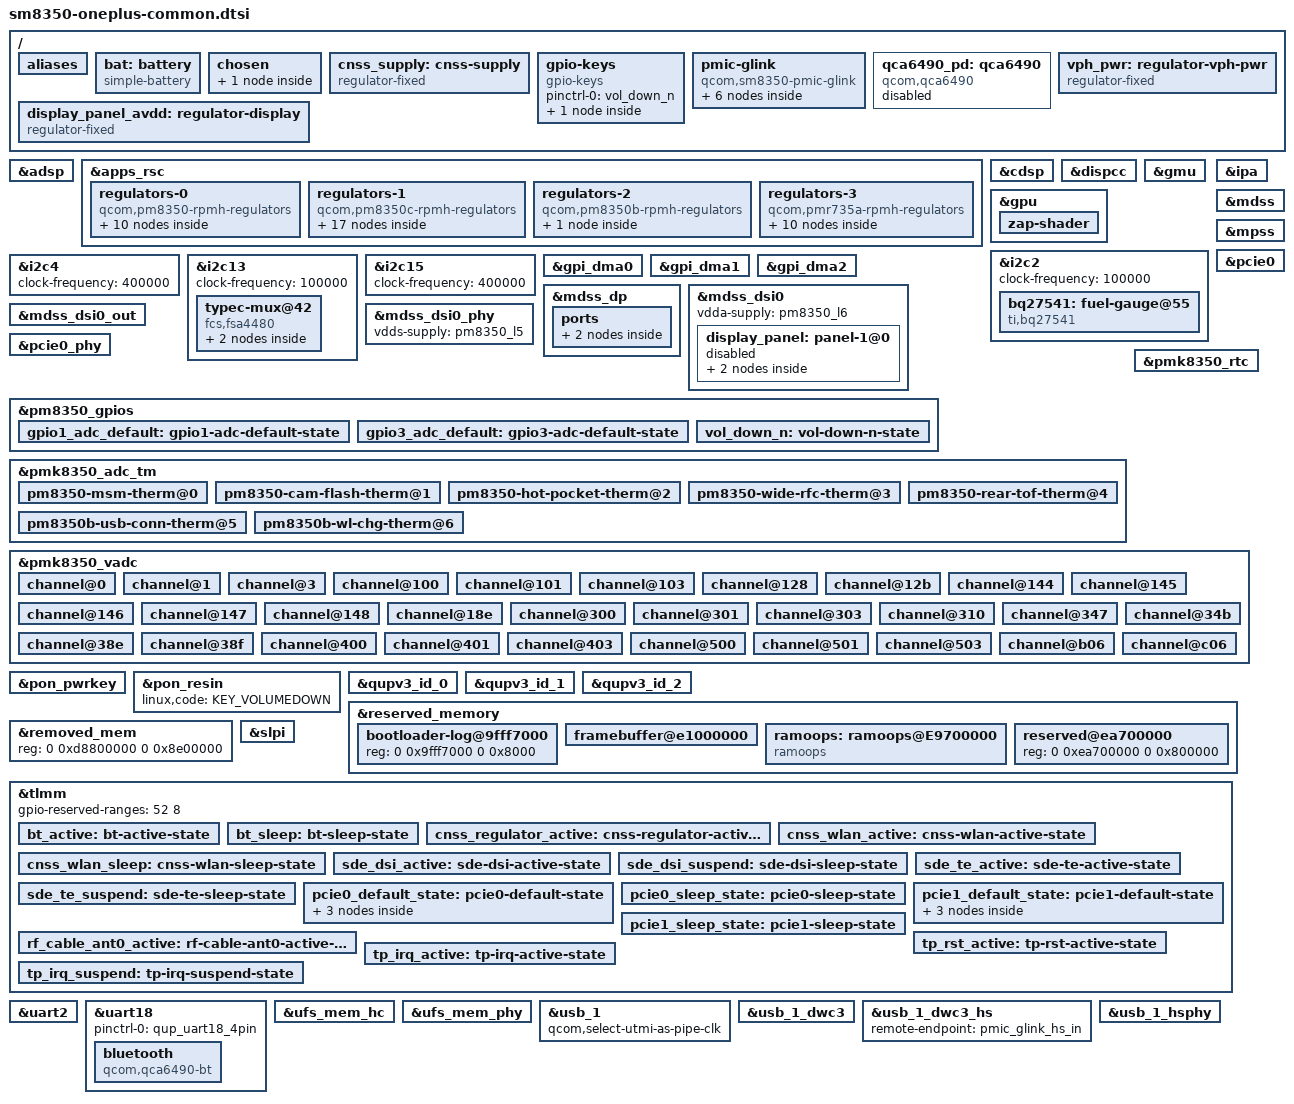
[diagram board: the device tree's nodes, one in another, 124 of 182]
// SPDX-License-Identifier: BSD-3-Clause
/*
 * Copyright (c) 2023 Igalia S.L.
 * Authors:
 *	Nia Espera <nespera@igalia.com>
 */

#include <dt-bindings/iio/qcom,spmi-adc7-pm8350.h>
#include <dt-bindings/iio/qcom,spmi-adc7-pm8350b.h>
#define SMB139x_1_SID 0x0b
#define SMB139x_2_SID 0x0c
#include <dt-bindings/iio/qcom,spmi-adc7-smb139x.h>
#include <dt-bindings/pinctrl/qcom,pmic-gpio.h>
#include <dt-bindings/regulator/qcom,rpmh-regulator.h>
#include "sm8350.dtsi"
#include "pm8350.dtsi"
#include "pm8350b.dtsi"
#include "pm8350c.dtsi"
#include "pmk8350.dtsi"
#include "pmr735a.dtsi"
#include "pmr735b.dtsi"

/ {
	chassis-type = "handset";
	interrupt-parent = <&intc>;

	aliases {
		bluetooth = &bluetooth;
		serial0 = &uart2;
		serial1 = &uart18;
	};

	bat: battery {
		compatible = "simple-battery";
		device-chemistry = "lithium-ion";
		voltage-min-design-microvolt = <3200000>;
		energy-full-design-microwatt-hours = <15840000>;
		charge-full-design-microamp-hours = <2225000>;
	};

	chosen {
		#address-cells = <2>;
		#size-cells = <2>;
		ranges;

		framebuffer: framebuffer@e4d00000 {
			compatible = "simple-framebuffer";
			reg = <0 0xe4d00000 0 0x2400000>;
			width = <1080>;
			height = <2412>;
			stride = <(1080 * 4)>;
			format = "a8r8g8b8";
			/*
			 * That's (going to be) a lot of clocks, but it's
			 * necessary due to unused clk cleanup & no panel
			 * driver yet.
			 */
			clocks = <&gcc GCC_DISP_HF_AXI_CLK>,
				 <&gcc GCC_DISP_SF_AXI_CLK>;
		};
	};

	cnss_supply: cnss-supply {
		compatible = "regulator-fixed";
		regulator-name = "wcnss_regulator";
		regulator-min-microvolt = <1900000>;
		regulator-max-microvolt = <1900000>;

		enable-active-high;

		pinctrl-0 = <&cnss_regulator_active>;
		pinctrl-names = "default";

		gpio = <&tlmm 201 GPIO_ACTIVE_HIGH>;
	};

	/*
	gpio_i2c4: gpio-i2c {
		compatible = "i2c-gpio";
		sda-gpios = <&tlmm 20 (GPIO_ACTIVE_HIGH|GPIO_OPEN_DRAIN)>;
		scl-gpios = <&tlmm 21 (GPIO_ACTIVE_HIGH|GPIO_OPEN_DRAIN)>;
		//#address-cells = <1>;
		//#size-cells = <0>;

		pinctrl-names = "default";
		pinctrl-0 = <&qup_i2c4_default>, <&tp_enable_2v8>;
	};
	*/

	gpio-keys {
		compatible = "gpio-keys";

		pinctrl-0 = <&vol_down_n>;
		pinctrl-names = "default";

		key-vol-down {
			label = "Volume Down";
			linux,code = <KEY_VOLUMEDOWN>;
			gpios = <&pm8350_gpios 6 GPIO_ACTIVE_LOW>;
			debounce-interval = <15>;
			linux,can-disable;
			wakeup-source;
		};
	};

	pmic-glink {
		compatible = "qcom,sm8350-pmic-glink", "qcom,pmic-glink";
		#address-cells = <1>;
		#size-cells = <0>;

		connector@0 {
			compatible = "usb-c-connector";
			reg = <0>;
			power-role = "dual";
			data-role = "dual";

			ports {
				#address-cells = <1>;
				#size-cells = <0>;

				port@0 {
					reg = <0>;

					pmic_glink_hs_in: endpoint {
						remote-endpoint = <&usb_1_dwc3_hs>;
					};
				};

				/* USB3 not working, so no port@1 */

				port@2 {
					reg = <2>;

					pmic_glink_sbu: endpoint {
						remote-endpoint = <&fsa4480_sbu_mux>;
					};
				};
			};
		};
	};

	qca6490_pd: qca6490 {
		compatible = "qcom,qca6490";
		#power-domain-cells = <0>;

		vddaonbt-supply = <&pm8350_s11>;
		vddaonwl-supply = <&pmr735a_s2>;
		vddasd-supply = <&pmr735a_l7>;
		vddrfa1-supply = <&pm8350c_s1>;
		vddrfa2-supply = <&pm8350_s12>;
		vddrfa3-supply = <&pm8350c_s1>;
		vddpcie1-supply = <&cnss_supply>;
		vddpcie2-supply = <&pm8350c_s1>;
		vddio-supply = <&pm8350_s10>;

		pinctrl-0 = <&cnss_wlan_sleep>;
		pinctrl-1 = <&cnss_wlan_active>;
		pinctrl-names = "default", "active";

		status = "disabled";
	};

	display_panel_avdd: regulator-display {
		compatible = "regulator-fixed";
		regulator-name = "display_panel_avdd";
		regulator-min-microvolt = <5500000>;
		regulator-max-microvolt = <5500000>;
		regulator-enable-ramp-delay = <233>;

		enable-active-high;
		regulator-boot-on;
	};

	vph_pwr: regulator-vph-pwr {
		compatible = "regulator-fixed";
		regulator-name = "vph_pwr";
		regulator-min-microvolt = <3700000>;
		regulator-max-microvolt = <3700000>;

		regulator-always-on;
		regulator-boot-on;
	};
};

&adsp {
	firmware-name = "qcom/sm8350/OnePlus/lemonade/adsp.mbn";
	status = "okay";
};

&apps_rsc {
	regulators-0 {
		compatible = "qcom,pm8350-rpmh-regulators";
		qcom,pmic-id = "b";

		vdd-s1-supply = <&vph_pwr>;
		vdd-s2-supply = <&vph_pwr>;
		vdd-s3-supply = <&vph_pwr>;
		vdd-s4-supply = <&vph_pwr>;
		vdd-s5-supply = <&vph_pwr>;
		vdd-s6-supply = <&vph_pwr>;
		vdd-s7-supply = <&vph_pwr>;
		vdd-s8-supply = <&vph_pwr>;
		vdd-s9-supply = <&vph_pwr>;
		vdd-s10-supply = <&vph_pwr>;
		vdd-s11-supply = <&vph_pwr>;
		vdd-s12-supply = <&vph_pwr>;

		vdd-l1-l4-supply = <&pm8350_s11>;
		vdd-l2-l7-supply = <&vreg_bob>;
		vdd-l3-l5-supply = <&vreg_bob>;
		vdd-l6-l9-l10-supply = <&pm8350_s11>;
		vdd-l8-supply = <&pmr735a_s2>;

		/*
		 * ARC regulators:
		 * S5 - mx.lvl
		 * S6 - gfx.lvl
		 * S9 - mxc.lvl
		 */

		pm8350_s10: smps10 {
			regulator-name = "pm8350_s10";
			regulator-min-microvolt = <1800000>;
			regulator-max-microvolt = <1800000>;
			regulator-initial-mode = <RPMH_REGULATOR_MODE_HPM>;
		};

		pm8350_s11: smps11 {
			regulator-name = "pm8350_s11";
			regulator-min-microvolt = <752000>;
			regulator-max-microvolt = <1012000>;
			regulator-initial-mode = <RPMH_REGULATOR_MODE_HPM>;
		};

		pm8350_s12: smps12 {
			regulator-name = "pm8350_s12";
			regulator-min-microvolt = <1224000>;
			regulator-max-microvolt = <1360000>;
			regulator-initial-mode = <RPMH_REGULATOR_MODE_HPM>;
		};

		pm8350_l1: ldo1 {
			regulator-name = "pm8350_l1";
			regulator-min-microvolt = <912000>;
			regulator-max-microvolt = <920000>;
			regulator-initial-mode = <RPMH_REGULATOR_MODE_HPM>;
		};

		pm8350_l2: ldo2 {
			regulator-name = "pm8350_l2";
			regulator-min-microvolt = <3072000>;
			regulator-max-microvolt = <3072000>;
			regulator-initial-mode = <RPMH_REGULATOR_MODE_HPM>;
		};

		pm8350_l3: ldo3 {
			regulator-name = "pm8350_l3";
			regulator-min-microvolt = <904000>;
			regulator-max-microvolt = <904000>;
			regulator-initial-mode = <RPMH_REGULATOR_MODE_HPM>;
		};

		/* L4 - lmx.lvl (ARC) */

		pm8350_l5: ldo5 {
			regulator-name = "pm8350_l5";
			regulator-min-microvolt = <880000>;
			regulator-max-microvolt = <888000>;
			regulator-initial-mode = <RPMH_REGULATOR_MODE_HPM>;
			regulator-allow-set-load;
			regulator-allowed-modes = <RPMH_REGULATOR_MODE_LPM
						   RPMH_REGULATOR_MODE_HPM>;
		};

		pm8350_l6: ldo6 {
			regulator-name = "pm8350_l6";
			regulator-min-microvolt = <1200000>;
			regulator-max-microvolt = <1208000>;
			regulator-initial-mode = <RPMH_REGULATOR_MODE_HPM>;
			regulator-allow-set-load;
			regulator-allowed-modes = <RPMH_REGULATOR_MODE_LPM
						   RPMH_REGULATOR_MODE_HPM>;
		};

		pm8350_l7: ldo7 {
			regulator-name = "pm8350_l7";
			regulator-min-microvolt = <2400000>;
			regulator-max-microvolt = <3008000>;
			regulator-initial-mode = <RPMH_REGULATOR_MODE_HPM>;
			regulator-allow-set-load;
			regulator-allowed-modes = <RPMH_REGULATOR_MODE_LPM
						   RPMH_REGULATOR_MODE_HPM>;
		};

		/* L8 - lcx.lvl (ARC) */

		pm8350_l9: ldo9 {
			regulator-name = "pm8350_l9";
			regulator-min-microvolt = <1200000>;
			regulator-max-microvolt = <1200000>;
			regulator-initial-mode = <RPMH_REGULATOR_MODE_HPM>;
			regulator-allow-set-load;
			regulator-allowed-modes = <RPMH_REGULATOR_MODE_LPM
						   RPMH_REGULATOR_MODE_HPM>;
		};
	};

	regulators-1 {
		compatible = "qcom,pm8350c-rpmh-regulators";
		qcom,pmic-id = "c";

		vdd-s1-supply = <&vph_pwr>;
		vdd-s2-supply = <&vph_pwr>;
		vdd-s3-supply = <&vph_pwr>;
		vdd-s4-supply = <&vph_pwr>;
		vdd-s5-supply = <&vph_pwr>;
		vdd-s6-supply = <&vph_pwr>;
		vdd-s7-supply = <&vph_pwr>;
		vdd-s8-supply = <&vph_pwr>;
		vdd-s9-supply = <&vph_pwr>;
		vdd-s10-supply = <&vph_pwr>;

		vdd-l1-l12-supply = <&pm8350c_s1>;
		vdd-l2-l8-supply = <&pm8350c_s1>;
		vdd-l3-l4-l5-l7-l13-supply = <&vreg_bob>;
		vdd-l6-l9-l11-supply = <&vreg_bob>;
		vdd-l10-supply = <&pm8350_s12>;

		vdd-bob-supply = <&vph_pwr>;

		pm8350c_s1: smps1 {
			regulator-name = "pm8350c_s1";
			regulator-min-microvolt = <1800000>;
			regulator-max-microvolt = <1952000>;
			regulator-initial-mode = <RPMH_REGULATOR_MODE_HPM>;
		};

		/* S2 - ebi.lvl (ARC) */

		pm8350c_s3: smps3 {
			regulator-name = "pm8350c_s3";
			regulator-min-microvolt = <300000>;
			regulator-max-microvolt = <704000>;
			regulator-initial-mode = <RPMH_REGULATOR_MODE_HPM>;
		};

		/*
		 * ARC regulators:
		 * S4 - mss.lvl
		 * S6 - cx.lvl
		 * S8 - mmcx.lvl
		 */

		pm8350c_s10: smps10 {
			regulator-name = "pm8350c_s10";
			regulator-min-microvolt = <1048000>;
			regulator-max-microvolt = <1128000>;
			regulator-initial-mode = <RPMH_REGULATOR_MODE_HPM>;
		};

		pm8350c_l1: ldo1 {
			regulator-name = "pm8350c_l1";
			regulator-min-microvolt = <1800000>;
			regulator-max-microvolt = <1800000>;
			regulator-initial-mode = <RPMH_REGULATOR_MODE_HPM>;
		};

		pm8350c_l2: ldo2 {
			regulator-name = "pm8350c_l2";
			regulator-min-microvolt = <1800000>;
			regulator-max-microvolt = <1800000>;
			regulator-initial-mode = <RPMH_REGULATOR_MODE_HPM>;
		};

		pm8350c_l3: ldo3 {
			regulator-name = "pm8350c_l3";
			regulator-min-microvolt = <3000000>;
			regulator-max-microvolt = <3300000>;
			regulator-initial-mode = <RPMH_REGULATOR_MODE_HPM>;
		};

		pm8350c_l4: ldo4 {
			regulator-name = "pm8350c_l4";
			regulator-min-microvolt = <1704000>;
			regulator-max-microvolt = <3000000>;
			regulator-initial-mode = <RPMH_REGULATOR_MODE_HPM>;
		};

		pm8350c_l5: ldo5 {
			regulator-name = "pm8350c_l5";
			regulator-min-microvolt = <1704000>;
			regulator-max-microvolt = <3000000>;
			regulator-initial-mode = <RPMH_REGULATOR_MODE_HPM>;
		};

		pm8350c_l6: ldo6 {
			regulator-name = "pm8350c_l6";
			regulator-min-microvolt = <1800000>;
			regulator-max-microvolt = <2960000>;
			regulator-initial-mode = <RPMH_REGULATOR_MODE_HPM>;
		};

		pm8350c_l7: ldo7 {
			regulator-name = "pm8350c_l7";
			regulator-min-microvolt = <3008000>;
			regulator-max-microvolt = <3008000>;
			regulator-initial-mode = <RPMH_REGULATOR_MODE_HPM>;
		};

		pm8350c_l8: ldo8 {
			regulator-name = "pm8350c_l8";
			regulator-min-microvolt = <1800000>;
			regulator-max-microvolt = <1800000>;
			regulator-initial-mode = <RPMH_REGULATOR_MODE_HPM>;
		};

		pm8350c_l9: ldo9 {
			regulator-name = "pm8350c_l9";
			regulator-min-microvolt = <2800000>;
			regulator-max-microvolt = <3008000>;
			regulator-initial-mode = <RPMH_REGULATOR_MODE_HPM>;
		};

		pm8350c_l10: ldo10 {
			regulator-name = "pm8350c_l10";
			regulator-min-microvolt = <1200000>;
			regulator-max-microvolt = <1200000>;
			regulator-initial-mode = <RPMH_REGULATOR_MODE_HPM>;
		};

		pm8350c_l11: ldo11 {
			regulator-name = "pm8350c_l11";
			regulator-min-microvolt = <2400000>;
			regulator-max-microvolt = <3008000>;
			regulator-initial-mode = <RPMH_REGULATOR_MODE_HPM>;
		};

		pm8350c_l12: ldo12 {
			regulator-name = "pm8350c_l12";
			regulator-min-microvolt = <1800000>;
			regulator-max-microvolt = <2000000>;
			regulator-initial-mode = <RPMH_REGULATOR_MODE_HPM>;
		};

		pm8350c_l13: ldo13 {
			regulator-name = "pm8350c_l13";
			regulator-min-microvolt = <3000000>;
			regulator-max-microvolt = <3200000>;
			regulator-initial-mode = <RPMH_REGULATOR_MODE_HPM>;
		};

		vreg_bob: bob {
			regulator-name = "vreg_bob";
			regulator-min-microvolt = <3400000>;
			regulator-max-microvolt = <3960000>;
			regulator-initial-mode = <RPMH_REGULATOR_MODE_AUTO>;
		};
	};

	regulators-2 {
		compatible = "qcom,pm8350b-rpmh-regulators";
		qcom,pmic-id = "d";

		vdd-l1-supply = <&pm8350_s12>;

		pm8350b_l1: ldo1 {
			regulator-name = "pm8350b_l1";
			regulator-min-microvolt = <1200000>;
			regulator-max-microvolt = <1200000>;
			regulator-initial-mode = <RPMH_REGULATOR_MODE_HPM>;
			regulator-allowed-modes = <RPMH_REGULATOR_MODE_LPM
						   RPMH_REGULATOR_MODE_HPM>;
		};
	};

	regulators-3 {
		compatible = "qcom,pmr735a-rpmh-regulators";
		qcom,pmic-id = "e";

		vdd-s1-supply = <&vph_pwr>;
		vdd-s2-supply = <&vph_pwr>;
		vdd-s3-supply = <&vph_pwr>;

		vdd-l1-l2-supply = <&pmr735a_s2>;
		vdd-l3-supply = <&pmr735a_s1>;
		vdd-l4-supply = <&pm8350c_s1>;
		vdd-l5-l6-supply = <&pm8350c_s1>;
		vdd-l7-bob-supply = <&vreg_bob>;

		pmr735a_s1: smps1 {
			regulator-name = "pmr735a_s1";
			regulator-min-microvolt = <1200000>;
			regulator-max-microvolt = <1280000>;
		};

		pmr735a_s2: smps2 {
			regulator-name = "pmr735a_s2";
			regulator-min-microvolt = <500000>;
			regulator-max-microvolt = <976000>;
		};

		pmr735a_s3: smps3 {
			regulator-name = "pmr735a_s3";
			regulator-min-microvolt = <2208000>;
			regulator-max-microvolt = <2352000>;
		};

		pmr735a_l1: ldo1 {
			regulator-name = "pmr735a_l1";
			regulator-min-microvolt = <912000>;
			regulator-max-microvolt = <912000>;
		};

		pmr735a_l2: ldo2 {
			regulator-name = "pmr735a_l2";
			regulator-min-microvolt = <1200000>;
			regulator-max-microvolt = <1200000>;
		};

		pmr735a_l3: ldo3 {
			regulator-name = "pmr735a_l3";
			regulator-min-microvolt = <1200000>;
			regulator-max-microvolt = <1200000>;
		};

		pmr735a_l4: ldo4 {
			regulator-name = "pmr735a_l4";
			regulator-min-microvolt = <1776000>;
			regulator-max-microvolt = <1872000>;
		};

		pmr735a_l5: ldo5 {
			regulator-name = "pmr735a_l5";
			regulator-min-microvolt = <800000>;
			regulator-max-microvolt = <800000>;
		};

		pmr735a_l6: ldo6 {
			regulator-name = "pmr735a_l6";
			regulator-min-microvolt = <480000>;
			regulator-max-microvolt = <904000>;
		};

		pmr735a_l7: ldo7 {
			regulator-name = "pmr735a_l7";
			regulator-min-microvolt = <2800000>;
			regulator-max-microvolt = <2800000>;
		};
	};
};

&cdsp {
	firmware-name = "qcom/sm8350/OnePlus/lemonade/cdsp.mbn";
	status = "okay";
};

&dispcc {
	//status = "okay";
};

&gmu {
	/* FIXME: check_dtbs complains */
	//firmware-name = "qcom/sm8350/lemonade/a660_gmu.bin";
};

&gpu {
	//status = "okay";

	zap-shader {
		memory-region = <&pil_gpu_mem>;
		firmware-name = "qcom/sm8350/lemonade/a660_zap.mbn";
	};
};

&i2c2 {
	clock-frequency = <100000>;
	status = "okay";

	bq27541: fuel-gauge@55 {
		compatible = "ti,bq27541";
		reg = <0x55>;
		monitored-battery = <&bat>;
	};
};


&i2c4 {
	clock-frequency = <400000>;
	status = "okay";

	/* Touchscreens: Syna TCM oncell or Samsung s6sy761 */
};

&i2c13 {
	clock-frequency = <100000>;
	status = "okay";

	typec-mux@42 {
		compatible = "fcs,fsa4480";
		reg = <0x42>;

		interrupts-extended = <&tlmm 2 IRQ_TYPE_LEVEL_LOW>;

		vcc-supply = <&vreg_bob>;
		mode-switch;
		orientation-switch;

		port {
			fsa4480_sbu_mux: endpoint {
				remote-endpoint = <&pmic_glink_sbu>;
			};
		};
	};

	/* Qualcomm PM8008i/PM8008j @ 8, 9, c, d */
};

&i2c15 {
	clock-frequency = <400000>;
	status = "okay";

	/* sn-nci NFC controller @ 28 */
};

&gpi_dma0 {
	status = "okay";
};

&gpi_dma1 {
	status = "okay";
};

&gpi_dma2 {
	status = "okay";
};

&ipa {
	qcom,gsi-loader = "self";
	memory-region = <&pil_ipa_fw_mem>;
	firmware-name = "qcom/sm8350/OnePlus/lemonade/ipa_fws.mbn";
	status = "okay";
};

&mdss {
	//status = "okay";
};

&mdss_dp {
	//status = "okay";

	ports {
		port@1 {
			reg = <1>;

			endpoint {
			};
		};
	};
};

&mdss_dsi0 {
	vdda-supply = <&pm8350_l6>;

	//status = "okay";

	/* Common properties for OnePlus 9 and 9 Pro */
	display_panel: panel-1@0 {
		reg = <0>;

		pinctrl-0 = <&sde_dsi_active &sde_te_active>;
		pinctrl-1 = <&sde_dsi_suspend &sde_te_suspend>;
		pinctrl-names = "default", "sleep";

		reset-gpios = <&tlmm 24 GPIO_ACTIVE_LOW>;

		vdd-supply = <&pm8350c_l13>;
		vddio-supply = <&pm8350c_l12>;
		avdd-supply = <&display_panel_avdd>;
		//clocks = <&rpmhcc RPMH_DIV_CLK1>;
		//clock-names = "div_clk";
		//clocks = <&mdss_dsi0_phy DISP_CC_MDSS_>

		status = "disabled";

		port {
			panel_in: endpoint {
				remote-endpoint = <&mdss_dsi0_out>;
			};
		};
	};
};

&mdss_dsi0_out {
	remote-endpoint = <&panel_in>;
	data-lanes = <0 1 2 3>;
};

&mdss_dsi0_phy {
	vdds-supply = <&pm8350_l5>;
	//status = "okay";
};

&mpss {
	firmware-name = "qcom/sm8350/OnePlus/lemonade/modem.mbn";
};

&pcie0 {
	pinctrl-0 = <&pcie0_default_state>;//, <&pcie0_sleep_state>;
	pinctrl-names = "default";//, "sleep";

	//power-domains = <&qca6490_pd>;

	perst-gpios = <&tlmm 94 GPIO_ACTIVE_HIGH>;
	wake-gpios = <&tlmm 96 GPIO_ACTIVE_HIGH>;

	status = "okay";
};

&pcie0_phy {
	vdda-phy-supply = <&pm8350_l5>;
	vdda-pll-supply = <&pm8350_l6>;

	power-domains = <&qca6490_pd>;

	status = "okay";
};

&pm8350_gpios {
	gpio1_adc_default: gpio1-adc-default-state {
		pins = "gpio1";
		function = "normal";
		bias-high-impedance;
		bias-disable;
	};

	gpio3_adc_default: gpio3-adc-default-state {
		pins = "gpio3";
		function = "normal";
		bias-high-impedance;
		bias-disable;
	};

	vol_down_n: vol-down-n-state {
		pins = "gpio6";
		function = "normal";
		power-source = <1>;
		bias-pull-up;
		input-enable;
	};
};

&pmk8350_adc_tm {
	status = "okay";

	pm8350-msm-therm@0 {
		reg = <0>;
		io-channels = <&pmk8350_vadc PM8350_ADC7_AMUX_THM1_100K_PU(1)>;
		qcom,ratiometric;
		qcom,hw-settle-time-us = <200>;
	};

	pm8350-cam-flash-therm@1 {
		reg = <1>;
		io-channels = <&pmk8350_vadc PM8350_ADC7_AMUX_THM2_100K_PU(1)>;
		qcom,ratiometric;
		qcom,hw-settle-time-us = <200>;
	};

	pm8350-hot-pocket-therm@2 {
		reg = <2>;
		io-channels = <&pmk8350_vadc PM8350_ADC7_AMUX_THM3_100K_PU(1)>;
		qcom,ratiometric;
		qcom,hw-settle-time-us = <200>;
	};

	pm8350-wide-rfc-therm@3 {
		reg = <3>;
		io-channels = <&pmk8350_vadc PM8350_ADC7_AMUX_THM4_100K_PU(1)>;
		qcom,ratiometric;
		qcom,hw-settle-time-us = <200>;
	};

	pm8350-rear-tof-therm@4 {
		reg = <4>;
		io-channels = <&pmk8350_vadc PM8350_ADC7_AMUX_THM5_100K_PU(1)>;
		qcom,ratiometric;
		qcom,hw-settle-time-us = <200>;
	};

	pm8350b-usb-conn-therm@5 {
		reg = <5>;
		io-channels = <&pmk8350_vadc PM8350B_ADC7_AMUX_THM4_100K_PU>;
		qcom,ratiometric;
		qcom,hw-settle-time-us = <200>;
	};

	pm8350b-wl-chg-therm@6 {
		reg = <6>;
		io-channels = <&pmk8350_vadc PM8350B_ADC7_GPIO2_100K_PU>;
		qcom,ratiometric;
		qcom,hw-settle-time-us = <200>;
	};
};

&pmk8350_rtc {
	status = "okay";
};

&pmk8350_vadc {
	pinctrl-0 = <&gpio1_adc_default>, <&gpio3_adc_default>;
	pinctrl-names = "default";

	channel@0 {
		reg = <0x00>;
		qcom,pre-scaling = <1 1>;
		label = "pmk8350_ref_gnd";
	};

	channel@1 {
		reg = <0x01>;
		qcom,pre-scaling = <1 1>;
		label = "pmk8350_vref_1p25";
	};

	channel@3 {
		reg = <0x03>;
		qcom,pre-scaling = <1 1>;
		label = "pmk8350_die_temp";
	};

	channel@100 {
		reg = <0x100>;
		qcom,pre-scaling = <1 1>;
		label = "pm8350_ref_gnd";
	};

	channel@101 {
		reg = <0x101>;
		qcom,pre-scaling = <1 1>;
		label = "pm8350_vref_1p25";
	};

	channel@103 {
		reg = <0x103>;
		qcom,pre-scaling = <1 1>;
		label = "pm8350_die_temp";
	};

	channel@128 {
		reg = <0x128>;
		qcom,ratiometric;
		qcom,hw-settle-time = <700>;
		qcom,pre-scaling = <1 1>;
		label = "gpio1_v";
	};

	channel@12b {
		reg = <0x12b>;
		qcom,ratiometric;
		qcom,hw-settle-time = <700>;
		qcom,pre-scaling = <1 1>;
		label = "gpio3_v";
	};

	channel@144 {
		reg = <PM8350_ADC7_AMUX_THM1_100K_PU(1)>;
		qcom,ratiometric;
		qcom,hw-settle-time = <200>;
		qcom,pre-scaling = <1 1>;
		label = "pm8350_msm_therm";
	};

	channel@145 {
		reg = <PM8350_ADC7_AMUX_THM2_100K_PU(1)>;
		qcom,ratiometric;
		qcom,hw-settle-time = <200>;
		qcom,pre-scaling = <1 1>;
		label = "pm8350_cam_flash_therm";
	};

	channel@146 {
		reg = <PM8350_ADC7_AMUX_THM3_100K_PU(1)>;
		qcom,ratiometric;
		qcom,hw-settle-time = <200>;
		qcom,pre-scaling = <1 1>;
		label = "pm8350_hot_pocket_therm";
	};

	channel@147 {
		reg = <PM8350_ADC7_AMUX_THM4_100K_PU(1)>;
		qcom,ratiometric;
		qcom,hw-settle-time = <200>;
		qcom,pre-scaling = <1 1>;
		label = "pm8350_wide_rfc_therm";
	};

	channel@148 {
		reg = <PM8350_ADC7_AMUX_THM5_100K_PU(1)>;
		qcom,ratiometric;
		qcom,hw-settle-time = <200>;
		qcom,pre-scaling = <1 1>;
		label = "pm8350_rear_tof_therm";
	};

	channel@18e {
		reg = <0x18e>;
		qcom,pre-scaling = <1 3>;
		label = "pm8350_vph_pwr";
	};

	channel@300 {
		reg = <0x300>;
		qcom,pre-scaling = <1 1>;
		label = "pm8350b_ref_gnd";
	};

	channel@301 {
		reg = <0x301>;
		qcom,pre-scaling = <1 1>;
		label = "pm8350b_vref_1p25";
	};

	channel@303 {
		reg = <0x303>;
		qcom,pre-scaling = <1 1>;
		label = "pm8350b_die_temp";
	};

	channel@310 {
		reg = <PM8350B_ADC7_CHG_TEMP>;
		qcom,pre-scaling = <1 1>;
		label = "pm8350b_chg_temp";
	};

	channel@347 {
		reg = <PM8350B_ADC7_AMUX_THM4_100K_PU>;
		qcom,ratiometric;
		qcom,hw-settle-time = <200>;
		qcom,pre-scaling = <1 1>;
		label = "pm8350b_usb_conn_therm";
	};

	channel@34b {
		reg = <PM8350B_ADC7_GPIO2_100K_PU>;
		qcom,ratiometric;
		qcom,hw-settle-time = <200>;
		qcom,pre-scaling = <1 1>;
		label = "pm8350b_wl_chg_therm";
	};

	channel@38e {
		reg = <0x38e>;
		qcom,pre-scaling = <1 3>;
		label = "pm8350b_vph_pwr";
	};

	channel@38f {
		reg = <0x38f>;
		qcom,pre-scaling = <1 3>;
		label = "pm8350b_vbat_sns";
	};

	channel@400 {
		reg = <0x400>;
		qcom,pre-scaling = <1 1>;
		label = "pmr735a_ref_gnd";
	};

	channel@401 {
		reg = <0x401>;
		qcom,pre-scaling = <1 1>;
		label = "pmr735a_vref_1p25";
	};

	channel@403 {
		reg = <0x403>;
		qcom,pre-scaling = <1 1>;
		label = "pmr735a_die_temp";
	};

	channel@500 {
		reg = <0x500>;
		qcom,pre-scaling = <1 1>;
		label = "pmr735b_ref_gnd";
	};

	channel@501 {
		reg = <0x501>;
		qcom,pre-scaling = <1 1>;
		label = "pmr735b_vref_1p25";
	};

	channel@503 {
		reg = <0x503>;
		qcom,pre-scaling = <1 1>;
		label = "pmr735b_die_temp";
	};

	channel@b06 {
		reg = <SMB139x_1_ADC7_SMB_TEMP>;
		qcom,pre-scaling = <1 1>;
		label = "smb139x_1_smb_temp";
	};

	channel@c06 {
		reg = <SMB139x_2_ADC7_SMB_TEMP>;
		qcom,pre-scaling = <1 1>;
		label = "smb139x_2_smb_temp";
	};
};

&pon_pwrkey {
	status = "okay";
};

&pon_resin {
	linux,code = <KEY_VOLUMEDOWN>;
	status = "okay";
};
/*
&qup_i2c4_default {
	function = "gpio";
	bias-disable;
};
*/
&qupv3_id_0 {
	status = "okay";
};

&qupv3_id_1 {
	status = "okay";
};

&qupv3_id_2 {
	status = "okay";
};

&reserved_memory {
	bootloader-log@9fff7000 {
		reg = <0 0x9fff7000 0 0x8000>;
	};

	framebuffer@e1000000 {
		reg = <0 0xe4d00000 0 0x2400000>;
		no-map;
	};

	ramoops: ramoops@E9700000 {
		compatible = "ramoops";
		reg = <0 0xe9700000 0 0x5b8000>;
		record-size = <0x40000>;
		console-size = <0x40000>;
		ftrace-size = <0x200000>;
		pmsg-size = <0x200000>;
		ecc-size = <0>;
	};

	reserved@ea700000 {
		reg = <0 0xea700000 0 0x800000>;
	};
};

&removed_mem {
	reg = <0 0xd8800000 0 0x8e00000>;
};

&slpi {
	firmware-name = "qcom/sm8350/OnePlus/lemonade/slpi.mbn";
	status = "okay";
};

&tlmm {
	/* Fingerprint sensor and NFC-related pins shouldn't be touched by us */
	gpio-reserved-ranges = <52 8>;

	bt_active: bt-active-state {
		pins = "gpio65";
		function = "gpio";
		drive-strength = <16>;
		output-high;
		bias-pull-up;
	};

	bt_sleep: bt-sleep-state {
		pins = "gpio65";
		function = "gpio";
		drive-strength = <2>;
		output-low;
		bias-pull-down;
	};

	cnss_regulator_active: cnss-regulator-active-state {
		pins = "gpio201";
		function = "gpio";
		drive-strength = <16>;
		bias-pull-down;
		output-low;
	};

	cnss_wlan_active: cnss-wlan-active-state {
		pins = "gpio64";
		function = "gpio";
		drive-strength = <16>;
		output-high;
		bias-pull-up;
	};

	cnss_wlan_sleep: cnss-wlan-sleep-state {
		pins = "gpio64";
		function = "gpio";
		drive-strength = <2>;
		output-low;
		bias-pull-down;
	};

	sde_dsi_active: sde-dsi-active-state {
		pins = "gpio24";
		function = "gpio";
		drive-strength = <8>;
		bias-disable;
	};

	sde_dsi_suspend: sde-dsi-sleep-state {
		pins = "gpio24";
		function = "gpio";
		drive-strength = <2>;
		bias-pull-down;
	};

	sde_te_active: sde-te-active-state {
		pins = "gpio82";
		function = "mdp_vsync";
		drive-strength = <2>;
		bias-pull-down;
	};

	sde_te_suspend: sde-te-sleep-state {
		pins = "gpio82";
		function = "mdp_vsync";
		drive-strength = <2>;
		bias-pull-down;
	};

	pcie0_default_state: pcie0-default-state {
		perst-pins {
			pins = "gpio94";
			function = "gpio";
			drive-strength = <2>;
			bias-pull-down;
		};

		clkreq-pins {
			pins = "gpio95";
			function = "pcie0_clkreqn";
			drive-strength = <2>;
			bias-pull-up;
		};

		wake-pins {
			pins = "gpio96";
			function = "gpio";
			drive-strength = <2>;
			bias-pull-up;
		};
	};

	pcie0_sleep_state: pcie0-sleep-state {
		pins = "gpio95";
		function = "gpio";
		drive-strength = <2>;
		bias-pull-up;
	};

	pcie1_default_state: pcie1-default-state {
		perst-pins {
			pins = "gpio97";
			function = "gpio";
			drive-strength = <2>;
			bias-pull-down;
		};

		clkreq-pins {
			pins = "gpio98";
			function = "pcie1_clkreqn";
			drive-strength = <2>;
			bias-pull-up;
		};

		wake-pins {
			pins = "gpio99";
			function = "gpio";
			drive-strength = <2>;
			bias-pull-up;
		};
	};

	/* XXX: Is this correct? */
	pcie1_sleep_state: pcie1-sleep-state {
		pins = "gpio98";
		function = "gpio";
		drive-strength = <2>;
		bias-pull-up;
	};

	/* Modem-related pin common on both devices */
	rf_cable_ant0_active: rf-cable-ant0-active-state {
		pins = "gpio165";
		function = "gpio";
		drive-strength = <2>;
		bias-pull-up;
	};

	tp_rst_active: tp-rst-active-state {
		pins = "gpio22";
		function = "gpio";
		drive-strength = <8>;
		bias-pull-up;
	};

	/* tp_rst_suspend pinctrl is different per device, don't specify here */

	tp_irq_active: tp-irq-active-state {
		pins = "gpio23";
		function = "gpio";
		drive-strength = <8>;
		bias-disable;
	};

	tp_irq_suspend: tp-irq-suspend-state {
		pins = "gpio23";
		function = "gpio";
		drive-strength = <2>;
		bias-pull-down;
	};
};

&uart2 {
	status = "okay";
};

&uart18 {
	pinctrl-0 = <&qup_uart18_4pin>;
	status = "okay";

	bluetooth: bluetooth {
		compatible = "qcom,qca6490-bt";

		pinctrl-0 = <&bt_active>;
		pinctrl-1 = <&bt_sleep>;
		pinctrl-names = "default", "sleep";

		/* QCA6490 requires wlan and bluetooth be enabled simultaneously */
		enable-gpios = <&tlmm 65 GPIO_ACTIVE_HIGH>;
		wlan-gpios = <&tlmm 64 GPIO_ACTIVE_HIGH>;
		swctrl-gpios = <&tlmm 153 GPIO_ACTIVE_HIGH>;

		power-domains = <&qca6490_pd>;

		//vddio-supply = <&pm8350_s10>;
		//vddaon-supply = <&pm8350_s11>;
		//vddasd-supply = <&pmr735a_l7>;
		//vdddig-supply = <&pm8350_s11>;
		//vddrfa1-supply = <&pm8350c_s1>;
		//vddrfa2-supply = <&pm8350_s12>;
		//vddpcie1-supply = <&pm8350_s12>;
		//vddpcie2-supply = <&pm8350c_s1>;

		max-speed = <3200000>;

		//status = "disabled";
	};
};

&ufs_mem_hc {
	reset-gpios = <&tlmm 203 GPIO_ACTIVE_LOW>;

	vcc-supply = <&pm8350_l7>;
	vcc-max-microamp = <800000>;
	vccq-supply = <&pm8350_l9>;
	vccq-max-microamp = <900000>;

	status = "okay";
};

&ufs_mem_phy {
	vdda-phy-supply = <&pm8350_l5>;
	vdda-pll-supply = <&pm8350_l6>;

	status = "okay";
};

&usb_1 {
	/*
	 * Bug in interconnect driver breaks USB; RPMh is unable to power on
	 * USB regulators without this.
	 */
	/delete-property/ interconnects;
	/delete-property/ interconnect-names;

	/* USB3 seems broken (though it's enabled downstream?) */
	qcom,select-utmi-as-pipe-clk;

	status = "okay";
};

&usb_1_dwc3 {
	dr_mode = "otg";
	maximum-speed = "high-speed";
	phys = <&usb_1_hsphy>;
	phy-names = "usb2-phy";
};

&usb_1_dwc3_hs {
	remote-endpoint = <&pmic_glink_hs_in>;
};

&usb_1_hsphy {
	vdda-pll-supply = <&pm8350_l5>;
	vdda18-supply = <&pm8350c_l1>;
	vdda33-supply = <&pm8350_l2>;

	status = "okay";
};
